AUTOSAR XML (schema 00044)
package /ComponentTypes
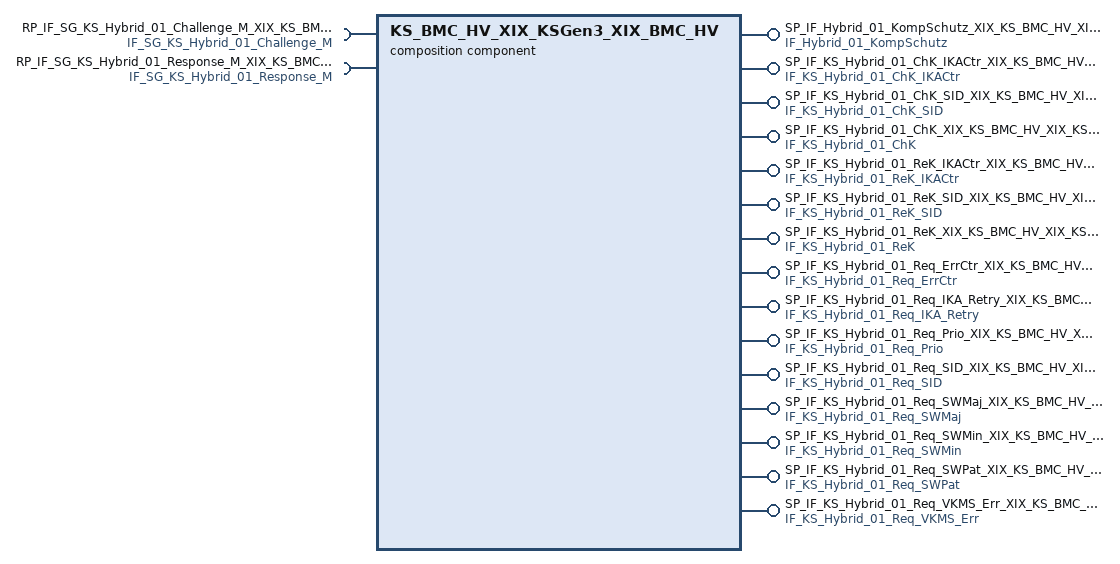
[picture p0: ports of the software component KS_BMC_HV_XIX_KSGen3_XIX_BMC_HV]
  composition sw component type KS_BMC_HV_XIX_KSGen3_XIX_BMC_HV
    15 x provide port:
      SP_IF_Hybrid_01_KompSchutz_XIX_KS_BMC_HV_XIX_KSGen3_XIX_BMC_HV: nonqueued-sender-com-spec=DE_Hybrid_01_KompSchutz, provided-interface=IF_Hybrid_01_KompSchutz
      SP_IF_KS_Hybrid_01_ChK_IKACtr_XIX_KS_BMC_HV_XIX_KSGen3_XIX_BMC_HV: nonqueued-sender-com-spec=DE_KS_Hybrid_01_ChK_IKACtr, provided-interface=IF_KS_Hybrid_01_ChK_IKACtr
      SP_IF_KS_Hybrid_01_ChK_SID_XIX_KS_BMC_HV_XIX_KSGen3_XIX_BMC_HV: nonqueued-sender-com-spec=DE_KS_Hybrid_01_ChK_SID, provided-interface=IF_KS_Hybrid_01_ChK_SID
      SP_IF_KS_Hybrid_01_ChK_XIX_KS_BMC_HV_XIX_KSGen3_XIX_BMC_HV: nonqueued-sender-com-spec=DE_KS_Hybrid_01_ChK, provided-interface=IF_KS_Hybrid_01_ChK
      SP_IF_KS_Hybrid_01_ReK_IKACtr_XIX_KS_BMC_HV_XIX_KSGen3_XIX_BMC_HV: nonqueued-sender-com-spec=DE_KS_Hybrid_01_ReK_IKACtr, provided-interface=IF_KS_Hybrid_01_ReK_IKACtr
      SP_IF_KS_Hybrid_01_ReK_SID_XIX_KS_BMC_HV_XIX_KSGen3_XIX_BMC_HV: nonqueued-sender-com-spec=DE_KS_Hybrid_01_ReK_SID, provided-interface=IF_KS_Hybrid_01_ReK_SID
      SP_IF_KS_Hybrid_01_ReK_XIX_KS_BMC_HV_XIX_KSGen3_XIX_BMC_HV: nonqueued-sender-com-spec=DE_KS_Hybrid_01_ReK, provided-interface=IF_KS_Hybrid_01_ReK
      SP_IF_KS_Hybrid_01_Req_ErrCtr_XIX_KS_BMC_HV_XIX_KSGen3_XIX_BMC_HV: nonqueued-sender-com-spec=DE_KS_Hybrid_01_Req_ErrCtr, provided-interface=IF_KS_Hybrid_01_Req_ErrCtr
      SP_IF_KS_Hybrid_01_Req_IKA_Retry_XIX_KS_BMC_HV_XIX_KSGen3_XIX_BMC_HV: nonqueued-sender-com-spec=DE_KS_Hybrid_01_Req_IKA_Retry, provided-interface=IF_KS_Hybrid_01_Req_IKA_Retry
      SP_IF_KS_Hybrid_01_Req_Prio_XIX_KS_BMC_HV_XIX_KSGen3_XIX_BMC_HV: nonqueued-sender-com-spec=DE_KS_Hybrid_01_Req_Prio, provided-interface=IF_KS_Hybrid_01_Req_Prio
      SP_IF_KS_Hybrid_01_Req_SID_XIX_KS_BMC_HV_XIX_KSGen3_XIX_BMC_HV: nonqueued-sender-com-spec=DE_KS_Hybrid_01_Req_SID, provided-interface=IF_KS_Hybrid_01_Req_SID
      SP_IF_KS_Hybrid_01_Req_SWMaj_XIX_KS_BMC_HV_XIX_KSGen3_XIX_BMC_HV: nonqueued-sender-com-spec=DE_KS_Hybrid_01_Req_SWMaj, provided-interface=IF_KS_Hybrid_01_Req_SWMaj
      SP_IF_KS_Hybrid_01_Req_SWMin_XIX_KS_BMC_HV_XIX_KSGen3_XIX_BMC_HV: nonqueued-sender-com-spec=DE_KS_Hybrid_01_Req_SWMin, provided-interface=IF_KS_Hybrid_01_Req_SWMin
      SP_IF_KS_Hybrid_01_Req_SWPat_XIX_KS_BMC_HV_XIX_KSGen3_XIX_BMC_HV: nonqueued-sender-com-spec=DE_KS_Hybrid_01_Req_SWPat, provided-interface=IF_KS_Hybrid_01_Req_SWPat
      SP_IF_KS_Hybrid_01_Req_VKMS_Err_XIX_KS_BMC_HV_XIX_KSGen3_XIX_BMC_HV: nonqueued-sender-com-spec=DE_KS_Hybrid_01_Req_VKMS_Err, provided-interface=IF_KS_Hybrid_01_Req_VKMS_Err
    require port RP_IF_SG_KS_Hybrid_01_Challenge_M_XIX_KS_BMC_HV_XIX_KSGen3_XIX_BMC_HV: nonqueued-receiver-com-spec=DE_SG_KS_Hybrid_01_Challenge_M, required-interface=IF_SG_KS_Hybrid_01_Challenge_M
    require port RP_IF_SG_KS_Hybrid_01_Response_M_XIX_KS_BMC_HV_XIX_KSGen3_XIX_BMC_HV: nonqueued-receiver-com-spec=DE_SG_KS_Hybrid_01_Response_M, required-interface=IF_SG_KS_Hybrid_01_Response_M
